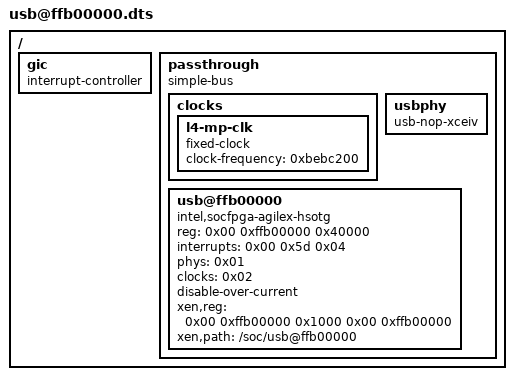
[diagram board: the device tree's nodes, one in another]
/* SPDX-License-Identifier: MIT-0 */
/dts-v1/;

/ {
	#address-cells = <0x02>;
	#size-cells = <0x01>;

	gic {
		#interrupt-cells = <0x03>;
		interrupt-controller;
	};

	passthrough {
		compatible = "simple-bus";
		ranges;
		#address-cells = <0x02>;
		#size-cells = <0x01>;

		clocks {

			l4-mp-clk {
				#clock-cells = <0x00>;
				compatible = "fixed-clock";
				clock-frequency = <0xbebc200>;
				phandle = <0x02>;
			};
		};

		usbphy {
			#phy-cells = <0x00>;
			compatible = "usb-nop-xceiv";
			phandle = <0x01>;
		};

		usb@ffb00000 {
			compatible = "intel,socfpga-agilex-hsotg\0snps,dwc2";
			reg = <0x00 0xffb00000 0x40000>;
			interrupts = <0x00 0x5d 0x04>;
			phys = <0x01>;
			phy-names = "usb2-phy";
			clocks = <0x02>;
			clock-names = "otg";
			status = "okay";
			disable-over-current;
			xen,reg = <0x00 0xffb00000 0x1000 0x00 0xffb00000>;
			xen,path = "/soc/usb@ffb00000";
		};
	};
};
